CM_ "IMPORT _honda_common.dbc";
CM_ "IMPORT _bosch_2018.dbc";
CM_ "IMPORT _bosch_adas_2018.dbc";
CM_ "IMPORT _steering_sensors_a.dbc";
CM_ "IMPORT _gearbox_common.dbc";

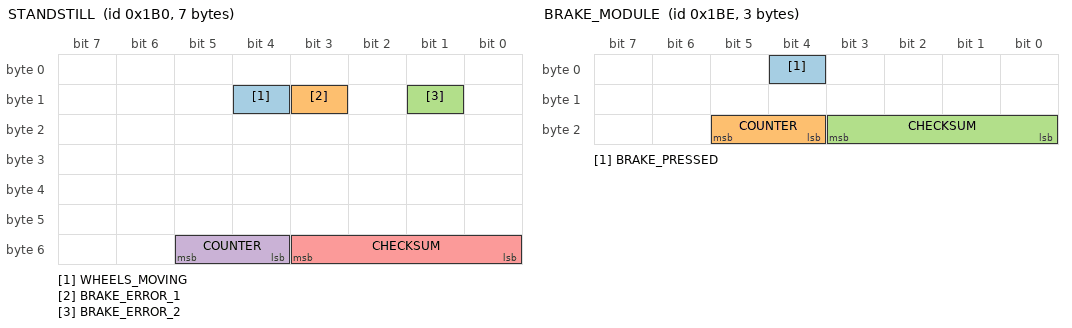
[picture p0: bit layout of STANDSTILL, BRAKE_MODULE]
BO_ 432 STANDSTILL: 7 VSA
 SG_ WHEELS_MOVING : 12|1@0+ (1,0) [0|1] "" EON
 SG_ BRAKE_ERROR_1 : 11|1@0+ (1,0) [0|1] "" EON
 SG_ BRAKE_ERROR_2 : 9|1@0+ (1,0) [0|1] "" EON
 SG_ COUNTER : 53|2@0+ (1,0) [0|3] "" EON
 SG_ CHECKSUM : 51|4@0+ (1,0) [0|15] "" EON

BO_ 446 BRAKE_MODULE: 3 VSA
 SG_ BRAKE_PRESSED : 4|1@0+ (1,0) [0|1] "" XXX
 SG_ COUNTER : 21|2@0+ (1,0) [0|3] "" XXX
 SG_ CHECKSUM : 19|4@0+ (1,0) [0|15] "" XXX

CM_ SG_ 479 RELATED_TO_GAS "bits 7, 3, and 1 set to 1 when gas not applied";
CM_ SG_ 479 GAS_BRAKE "Signed value, negative when braking and positive when applying gas";

VAL_ 545 ECON_ON_2 0 "off" 3 "on" ;
VAL_ 662 CRUISE_BUTTONS 7 "tbd" 6 "tbd" 5 "tbd" 4 "accel_res" 3 "decel_set" 2 "cancel" 1 "main" 0 "none" ;
VAL_ 662 CRUISE_SETTING 3 "distance_adj" 2 "tbd" 1 "lkas_button" 0 "none" ;
VAL_ 806 CMBS_BUTTON 3 "pressed" 0 "released" ;
